# PIC32CX1025SG61100 register map
Vendor: Microchip Technology; Series: PIC32CXSG61; File version: 0
CPU: CM4 r0p1, selectable endian, MPU, FPU, 3 interrupt priority bits, 137 interrupts
Registers are 32-bit, read-write, reset 0x0 unless marked. A register's access mark holds for its fields unless they carry their own. Offsets are from the block's base; [hi:lo] are bit positions; lines under a group give offsets from that group; {n}, {i} and the like mark numbered series; 'fields as' and 'values as' point back to an identical list.

## GMAC — Ethernet MAC
Base 0x42000800; register names take the prefix GMAC_
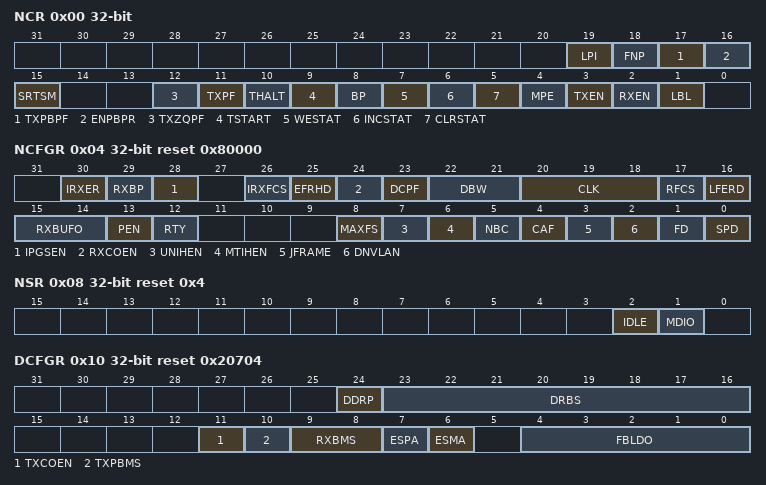
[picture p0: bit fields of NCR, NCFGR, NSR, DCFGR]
0x00 NCR — Network Control Register
  [19] LPI — Low Power Idle Enable
  [18] FNP — Flush Next Packet
  [17] TXPBPF — Transmit PFC Priority-based Pause Frame
  [16] ENPBPR — Enable PFC Priority-based Pause Reception
  [15] SRTSM — Store Receive Time Stamp to Memory
  [12] TXZQPF — Transmit Zero Quantum Pause Frame
  [11] TXPF — Transmit Pause Frame
  [10] THALT — Transmit Halt
  [9] TSTART — Start Transmission
  [8] BP — Back pressure
  [7] WESTAT — Write Enable for Statistics Registers
  [6] INCSTAT — Increment Statistics Registers
  [5] CLRSTAT — Clear Statistics Registers
  [4] MPE — Management Port Enable
  [3] TXEN — Transmit Enable
  [2] RXEN — Receive Enable
  [1] LBL — Loop Back Local
0x04 NCFGR reset 0x80000 — Network Configuration Register
  [30] IRXER — Ignore IPG GRXER
  [29] RXBP — Receive Bad Preamble
  [28] IPGSEN — IP Stretch Enable
  [26] IRXFCS — Ignore RX FCS
  [25] EFRHD — Enable Frames Received in Half Duplex
  [24] RXCOEN — Receive Checksum Offload Enable
  [23] DCPF — Disable Copy of Pause Frames
  [22:21] DBW — Data Bus Width
  [20:18] CLK — MDC CLock Division
    0=MCK8 (MCK divided by 8); 1=MCK16 (MCK divided by 16); 2=MCK32 (MCK divided by 32); 3=MCK48 (MCK divided by 48); 4=MCK64 (MCK divided by 64); 5=MCK96 (MCK divided by 96)
  [17] RFCS — Remove FCS
  [16] LFERD — Length Field Error Frame Discard
  [15:14] RXBUFO — Receive Buffer Offset
  [13] PEN — Pause Enable
  [12] RTY — Retry Test
  [8] MAXFS — 1536 Maximum Frame Size
  [7] UNIHEN — Unicast Hash Enable
  [6] MTIHEN — Multicast Hash Enable
  [5] NBC — No Broadcast
  [4] CAF — Copy All Frames
  [3] JFRAME — Jumbo Frame Size
  [2] DNVLAN — Discard Non-VLAN FRAMES
  [1] FD — Full Duplex
  [0] SPD — Speed
0x08 NSR ro reset 0x4 — Network Status Register
  [2] IDLE — PHY Management Logic Idle
  [1] MDIO — MDIO Input Status
0x0C UR — User Register
  [0] MII — MII Mode
0x10 DCFGR reset 0x20704 — DMA Configuration Register
  [24] DDRP — DMA Discard Receive Packets
  [23:16] DRBS — DMA Receive Buffer Size
  [11] TXCOEN — Transmitter Checksum Generation Offload Enable
  [10] TXPBMS — Transmitter Packet Buffer Memory Size Select
  [9:8] RXBMS — Receiver Packet Buffer Memory Size Select
    0=EIGHTH (RECEIVE_BUFFER_SIZE/8 Kbyte Memory Size); 1=QUARTER (RECEIVE_BUFFER_SIZE/4 Kbytes Memory Size); 2=HALF (RECEIVE_BUFFER_SIZE/2 Kbytes Memory Size); 3=FULL (RECEIVE_BUFFER_SIZE Kbytes Memory Size)
  [7] ESPA — Endian Swap Mode Enable for Packet Data Accesses
  [6] ESMA — Endian Swap Mode Enable for Management Descriptor Accesses
  [4:0] FBLDO — Fixed Burst Length for DMA Data Operations:
    1=SINGLE (00001: Always use SINGLE AHB bursts); 4=INCR4 (001xx: Attempt to use INCR4 AHB bursts (Default)); 8=INCR8 (01xxx: Attempt to use INCR8 AHB bursts); 16=INCR16 (1xxxx: Attempt to use INCR16 AHB bursts)
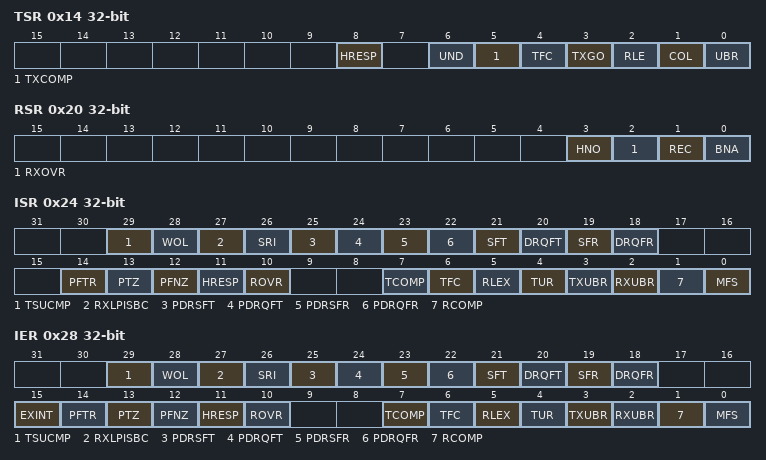
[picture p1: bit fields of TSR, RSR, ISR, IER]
0x14 TSR — Transmit Status Register
  [8] HRESP — HRESP Not OK
  [6] UND — Transmit Underrun
  [5] TXCOMP — Transmit Complete
  [4] TFC — Transmit Frame Corruption Due to AHB Error
  [3] TXGO — Transmit Go
  [2] RLE — Retry Limit Exceeded
  [1] COL — Collision Occurred
  [0] UBR — Used Bit Read
0x18 RBQB — Receive Buffer Queue Base Address
  [31:2] ADDR
0x1C TBQB — Transmit Buffer Queue Base Address
  [31:2] ADDR
0x20 RSR — Receive Status Register
  [3] HNO — HRESP Not OK
  [2] RXOVR — Receive Overrun
  [1] REC — Frame Received
  [0] BNA — Buffer Not Available
0x24 ISR — Interrupt Status Register
  [29] TSUCMP — Tsu timer comparison
  [28] WOL — Wake On LAN
  [27] RXLPISBC — Enable RX LPI Indication
  [26] SRI — TSU Seconds Register Increment
  [25] PDRSFT — PDelay Response Frame Transmitted
  [24] PDRQFT — PDelay Request Frame Transmitted
  [23] PDRSFR — PDelay Response Frame Received
  [22] PDRQFR — PDelay Request Frame Received
  [21] SFT — PTP Sync Frame Transmitted
  [20] DRQFT — PTP Delay Request Frame Transmitted
  [19] SFR — PTP Sync Frame Received
  [18] DRQFR — PTP Delay Request Frame Received
  [14] PFTR — Pause Frame Transmitted
  [13] PTZ — Pause Time Zero
  [12] PFNZ — Pause Frame with Non-zero Pause Quantum Received
  [11] HRESP — HRESP Not OK
  [10] ROVR — Receive Overrun
  [7] TCOMP — Transmit Complete
  [6] TFC — Transmit Frame Corruption Due to AHB Error
  [5] RLEX — Retry Limit Exceeded
  [4] TUR — Transmit Underrun
  [3] TXUBR — TX Used Bit Read
  [2] RXUBR — RX Used Bit Read
  [1] RCOMP — Receive Complete
  [0] MFS — Management Frame Sent
0x28 IER wo — Interrupt Enable Register
  [29] TSUCMP — Tsu timer comparison
  [28] WOL — Wake On LAN
  [27] RXLPISBC — Enable RX LPI Indication
  [26] SRI — TSU Seconds Register Increment
  [25] PDRSFT — PDelay Response Frame Transmitted
  [24] PDRQFT — PDelay Request Frame Transmitted
  [23] PDRSFR — PDelay Response Frame Received
  [22] PDRQFR — PDelay Request Frame Received
  [21] SFT — PTP Sync Frame Transmitted
  [20] DRQFT — PTP Delay Request Frame Transmitted
  [19] SFR — PTP Sync Frame Received
  [18] DRQFR — PTP Delay Request Frame Received
  [15] EXINT — External Interrupt
  [14] PFTR — Pause Frame Transmitted
  [13] PTZ — Pause Time Zero
  [12] PFNZ — Pause Frame with Non-zero Pause Quantum Received
  [11] HRESP — HRESP Not OK
  [10] ROVR — Receive Overrun
  [7] TCOMP — Transmit Complete
  [6] TFC — Transmit Frame Corruption Due to AHB Error
  [5] RLEX — Retry Limit Exceeded or Late Collision
  [4] TUR — Transmit Underrun
  [3] TXUBR — TX Used Bit Read
  [2] RXUBR — RX Used Bit Read
  [1] RCOMP — Receive Complete
  [0] MFS — Management Frame Sent
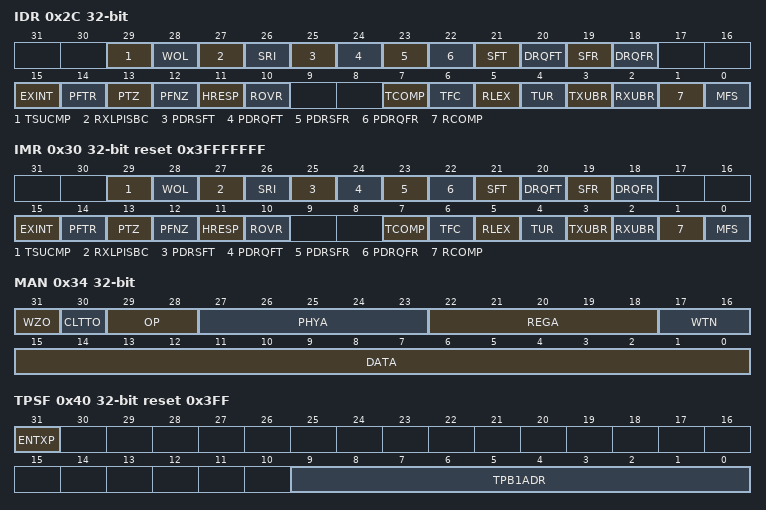
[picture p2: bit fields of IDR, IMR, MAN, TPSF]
0x2C IDR wo — Interrupt Disable Register
  fields as IER
0x30 IMR ro reset 0x3FFFFFFF — Interrupt Mask Register
  [29] TSUCMP — Tsu timer comparison
  [28] WOL — Wake On Lan
  [27] RXLPISBC — Enable RX LPI Indication
  [26] SRI — TSU Seconds Register Increment
  [25] PDRSFT — PDelay Response Frame Transmitted
  [24] PDRQFT — PDelay Request Frame Transmitted
  [23] PDRSFR — PDelay Response Frame Received
  [22] PDRQFR — PDelay Request Frame Received
  [21] SFT — PTP Sync Frame Transmitted
  [20] DRQFT — PTP Delay Request Frame Transmitted
  [19] SFR — PTP Sync Frame Received
  [18] DRQFR — PTP Delay Request Frame Received
  [15] EXINT — External Interrupt
  [14] PFTR — Pause Frame Transmitted
  [13] PTZ — Pause Time Zero
  [12] PFNZ — Pause Frame with Non-zero Pause Quantum Received
  [11] HRESP — HRESP Not OK
  [10] ROVR — Receive Overrun
  [7] TCOMP — Transmit Complete
  [6] TFC — Transmit Frame Corruption Due to AHB Error
  [5] RLEX — Retry Limit Exceeded
  [4] TUR — Transmit Underrun
  [3] TXUBR — TX Used Bit Read
  [2] RXUBR — RX Used Bit Read
  [1] RCOMP — Receive Complete
  [0] MFS — Management Frame Sent
0x34 MAN — PHY Maintenance Register
  [31] WZO — Write ZERO
  [30] CLTTO — Clause 22 Operation
  [29:28] OP — Operation
  [27:23] PHYA — PHY Address
  [22:18] REGA — Register Address
  [17:16] WTN — Write Ten
  [15:0] DATA — PHY Data
0x38 RPQ ro — Received Pause Quantum Register
  [15:0] RPQ — Received Pause Quantum
0x3C TPQ reset 0xFFFF — Transmit Pause Quantum Register
  [15:0] TPQ — Transmit Pause Quantum
0x40 TPSF reset 0x3FF — TX partial store and forward Register
  [31] ENTXP — Enable TX partial store and forward operation
  [9:0] TPB1ADR — TX packet buffer address
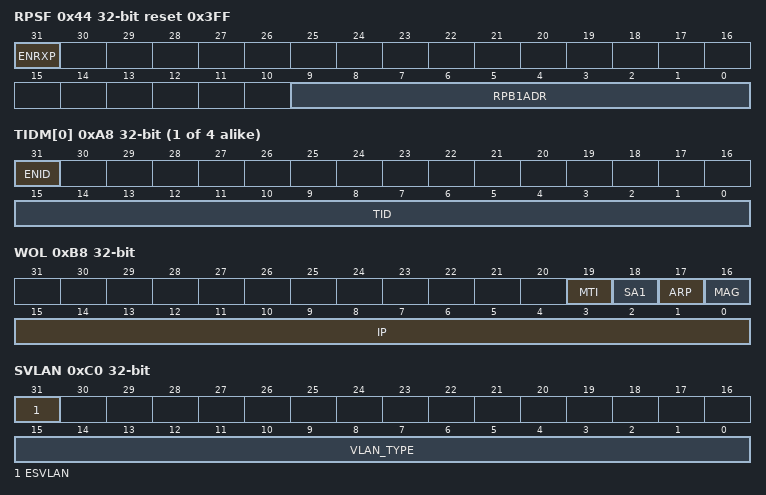
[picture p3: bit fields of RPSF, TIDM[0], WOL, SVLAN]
0x44 RPSF reset 0x3FF — RX partial store and forward Register
  [31] ENRXP — Enable RX partial store and forward operation
  [9:0] RPB1ADR — RX packet buffer address
0x48 RJFML reset 0x3FFF — RX Jumbo Frame Max Length Register
  [13:0] FML — Frame Max Length
0x80 HRB — Hash Register Bottom [31:0]
  [31:0] ADDR — Hash Address
0x84 HRT — Hash Register Top [63:32]
  [31:0] ADDR — Hash Address
{0x88+8i} SA[{i}] (i=0..3) group
  0x00 SAB — Specific Address Bottom [31:0] Register
    [31:0] ADDR — Specific Address 1
  0x04 SAT — Specific Address Top [47:32] Register
    [15:0] ADDR — Specific Address 1
{0xA8+4i} TIDM[{i}] (i=0..3) — Type ID Match n Register
  [31] ENID — Enable Copying of TID n Matched Frames
  [15:0] TID — Type ID Match n
0xB8 WOL — Wake on LAN
  [19] MTI — WOL LAN multicast
  [18] SA1 — WOL specific address reg 1
  [17] ARP — LAN ARP req
  [16] MAG — Event enable
  [15:0] IP — IP address
0xBC IPGS — IPG Stretch Register
  [15:0] FL — Frame Length
0xC0 SVLAN — Stacked VLAN Register
  [31] ESVLAN — Enable Stacked VLAN Processing Mode
  [15:0] VLAN_TYPE — User Defined VLAN_TYPE Field
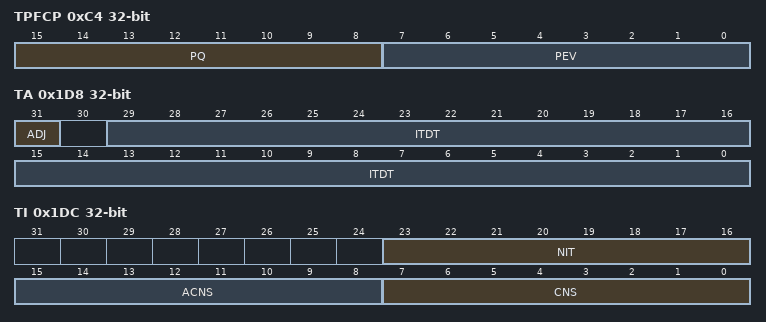
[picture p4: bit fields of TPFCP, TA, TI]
0xC4 TPFCP — Transmit PFC Pause Register
  [15:8] PQ — Pause Quantum
  [7:0] PEV — Priority Enable Vector
0xC8 SAMB1 — Specific Address 1 Mask Bottom [31:0] Register
  [31:0] ADDR — Specific Address 1 Mask
0xCC SAMT1 — Specific Address 1 Mask Top [47:32] Register
  [15:0] ADDR — Specific Address 1 Mask
0xDC NSC — Tsu timer comparison nanoseconds Register
  [20:0] NANOSEC — 1588 Timer Nanosecond comparison value
0xE0 SCL — Tsu timer second comparison Register
  [31:0] SEC — 1588 Timer Second comparison value
0xE4 SCH — Tsu timer second comparison Register
  [15:0] SEC — 1588 Timer Second comparison value
0xE8 EFTSH ro — PTP Event Frame Transmitted Seconds High Register
  [15:0] RUD — Register Update
0xEC EFRSH ro — PTP Event Frame Received Seconds High Register
  [15:0] RUD — Register Update
0xF0 PEFTSH ro — PTP Peer Event Frame Transmitted Seconds High Register
  [15:0] RUD — Register Update
0xF4 PEFRSH ro — PTP Peer Event Frame Received Seconds High Register
  [15:0] RUD — Register Update
0x100 OTLO ro — Octets Transmitted [31:0] Register
  [31:0] TXO — Transmitted Octets
0x104 OTHI ro — Octets Transmitted [47:32] Register
  [15:0] TXO — Transmitted Octets
0x108 FT ro — Frames Transmitted Register
  [31:0] FTX — Frames Transmitted without Error
0x10C BCFT ro — Broadcast Frames Transmitted Register
  [31:0] BFTX — Broadcast Frames Transmitted without Error
0x110 MFT ro — Multicast Frames Transmitted Register
  [31:0] MFTX — Multicast Frames Transmitted without Error
0x114 PFT ro — Pause Frames Transmitted Register
  [15:0] PFTX
0x118 BFT64 ro — 64 Byte Frames Transmitted Register
  [31:0] NFTX — 64 Byte Frames Transmitted without Error
0x11C TBFT127 ro — 65 to 127 Byte Frames Transmitted Register
  [31:0] NFTX — 65 to 127 Byte Frames Transmitted without Error
0x120 TBFT255 ro — 128 to 255 Byte Frames Transmitted Register
  [31:0] NFTX — 128 to 255 Byte Frames Transmitted without Error
0x124 TBFT511 ro — 256 to 511 Byte Frames Transmitted Register
  [31:0] NFTX — 256 to 511 Byte Frames Transmitted without Error
0x128 TBFT1023 ro — 512 to 1023 Byte Frames Transmitted Register
  [31:0] NFTX — 512 to 1023 Byte Frames Transmitted without Error
0x12C TBFT1518 ro — 1024 to 1518 Byte Frames Transmitted Register
  [31:0] NFTX — 1024 to 1518 Byte Frames Transmitted without Error
0x130 GTBFT1518 ro — Greater Than 1518 Byte Frames Transmitted Register
  [31:0] NFTX — Greater than 1518 Byte Frames Transmitted without Error
0x134 TUR ro — Transmit Underruns Register
  [9:0] TXUNR — Transmit Underruns
0x138 SCF ro — Single Collision Frames Register
  [17:0] SCOL — Single Collision
0x13C MCF ro — Multiple Collision Frames Register
  [17:0] MCOL — Multiple Collision
0x140 EC ro — Excessive Collisions Register
  [9:0] XCOL — Excessive Collisions
0x144 LC ro — Late Collisions Register
  [9:0] LCOL — Late Collisions
0x148 DTF ro — Deferred Transmission Frames Register
  [17:0] DEFT — Deferred Transmission
0x14C CSE ro — Carrier Sense Errors Register
  [9:0] CSR — Carrier Sense Error
0x150 ORLO ro — Octets Received [31:0] Received
  [31:0] RXO — Received Octets
0x154 ORHI ro — Octets Received [47:32] Received
  [15:0] RXO — Received Octets
0x158 FR ro — Frames Received Register
  [31:0] FRX — Frames Received without Error
0x15C BCFR ro — Broadcast Frames Received Register
  [31:0] BFRX — Broadcast Frames Received without Error
0x160 MFR ro — Multicast Frames Received Register
  [31:0] MFRX — Multicast Frames Received without Error
0x164 PFR ro — Pause Frames Received Register
  [15:0] PFRX
0x168 BFR64 ro — 64 Byte Frames Received Register
  [31:0] NFRX — 64 Byte Frames Received without Error
0x16C TBFR127 ro — 65 to 127 Byte Frames Received Register
  [31:0] NFRX — 65 to 127 Byte Frames Received without Error
0x170 TBFR255 ro — 128 to 255 Byte Frames Received Register
  [31:0] NFRX — 128 to 255 Byte Frames Received without Error
0x174 TBFR511 ro — 256 to 511Byte Frames Received Register
  [31:0] NFRX — 256 to 511 Byte Frames Received without Error
0x178 TBFR1023 ro — 512 to 1023 Byte Frames Received Register
  [31:0] NFRX — 512 to 1023 Byte Frames Received without Error
0x17C TBFR1518 ro — 1024 to 1518 Byte Frames Received Register
  [31:0] NFRX — 1024 to 1518 Byte Frames Received without Error
0x180 TMXBFR ro — 1519 to Maximum Byte Frames Received Register
  [31:0] NFRX — 1519 to Maximum Byte Frames Received without Error
0x184 UFR ro — Undersize Frames Received Register
  [9:0] UFRX — Undersize Frames Received
0x188 OFR ro — Oversize Frames Received Register
  [9:0] OFRX — Oversized Frames Received
0x18C JR ro — Jabbers Received Register
  [9:0] JRX — Jabbers Received
0x190 FCSE ro — Frame Check Sequence Errors Register
  [9:0] FCKR — Frame Check Sequence Errors
0x194 LFFE ro — Length Field Frame Errors Register
  [9:0] LFER — Length Field Frame Errors
0x198 RSE ro — Receive Symbol Errors Register
  [9:0] RXSE — Receive Symbol Errors
0x19C AE ro — Alignment Errors Register
  [9:0] AER — Alignment Errors
0x1A0 RRE ro — Receive Resource Errors Register
  [17:0] RXRER — Receive Resource Errors
0x1A4 ROE ro — Receive Overrun Register
  [9:0] RXOVR — Receive Overruns
0x1A8 IHCE ro — IP Header Checksum Errors Register
  [7:0] HCKER — IP Header Checksum Errors
0x1AC TCE ro — TCP Checksum Errors Register
  [7:0] TCKER — TCP Checksum Errors
0x1B0 UCE ro — UDP Checksum Errors Register
  [7:0] UCKER — UDP Checksum Errors
0x1BC TISUBN — 1588 Timer Increment [15:0] Sub-Nanoseconds Register
  [15:0] LSBTIR — Lower Significant Bits of Timer Increment
0x1C0 TSH — 1588 Timer Seconds High [15:0] Register
  [15:0] TCS — Timer Count in Seconds
0x1C8 TSSSL — 1588 Timer Sync Strobe Seconds [31:0] Register
  [31:0] VTS — Value of Timer Seconds Register Capture
0x1CC TSSN — 1588 Timer Sync Strobe Nanoseconds Register
  [29:0] VTN — Value Timer Nanoseconds Register Capture
0x1D0 TSL — 1588 Timer Seconds [31:0] Register
  [31:0] TCS — Timer Count in Seconds
0x1D4 TN — 1588 Timer Nanoseconds Register
  [29:0] TNS — Timer Count in Nanoseconds
0x1D8 TA wo — 1588 Timer Adjust Register
  [31] ADJ — Adjust 1588 Timer
  [29:0] ITDT — Increment/Decrement
0x1DC TI — 1588 Timer Increment Register
  [23:16] NIT — Number of Increments
  [15:8] ACNS — Alternative Count Nanoseconds
  [7:0] CNS — Count Nanoseconds
0x1E0 EFTSL ro — PTP Event Frame Transmitted Seconds Low Register
  [31:0] RUD — Register Update
0x1E4 EFTN ro — PTP Event Frame Transmitted Nanoseconds
  [29:0] RUD — Register Update
0x1E8 EFRSL ro — PTP Event Frame Received Seconds Low Register
  [31:0] RUD — Register Update
0x1EC EFRN ro — PTP Event Frame Received Nanoseconds
  [29:0] RUD — Register Update
0x1F0 PEFTSL ro — PTP Peer Event Frame Transmitted Seconds Low Register
  [31:0] RUD — Register Update
0x1F4 PEFTN ro — PTP Peer Event Frame Transmitted Nanoseconds
  [29:0] RUD — Register Update
0x1F8 PEFRSL ro — PTP Peer Event Frame Received Seconds Low Register
  [31:0] RUD — Register Update
0x1FC PEFRN ro — PTP Peer Event Frame Received Nanoseconds
  [29:0] RUD — Register Update
0x270 RLPITR ro — Receive LPI transition Register
  [15:0] RLPITR — Count number of times transition from rx normal idle to low power idle
0x274 RLPITI ro — Receive LPI Time Register
  [23:0] RLPITI — Increment once over 16 ahb clock when LPI indication bit 20 is set in rx mode
0x278 TLPITR ro — Receive LPI transition Register
  [15:0] TLPITR — Count number of times enable LPI tx bit 20 goes from low to high
0x27C TLPITI ro — Receive LPI Time Register
  [23:0] TLPITI — Increment once over 16 ahb clock when LPI indication bit 20 is set in tx mode

## Notices in the file
Copyright (c) 2022 Microchip Technology Inc.
SPDX-License-Identifier: Apache-2.0
Licensed under the Apache License, Version 2.0 (the "License");
you may not use this file except in compliance with the License.
You may obtain a copy of the License at
http://www.apache.org/licenses/LICENSE-2.0
Unless required by applicable law or agreed to in writing, software
distributed under the License is distributed on an "AS IS" BASIS,
WITHOUT WARRANTIES OR CONDITIONS OF ANY KIND, either express or implied.
See the License for the specific language governing permissions and
limitations under the License.
